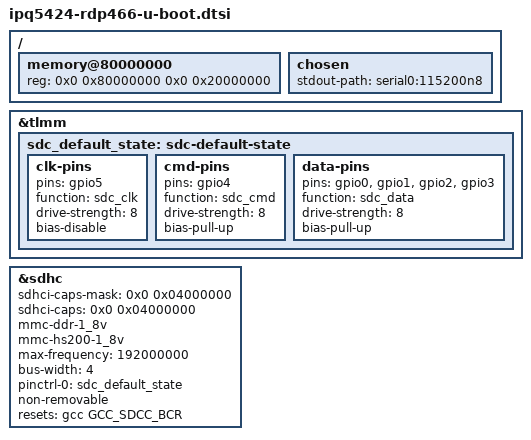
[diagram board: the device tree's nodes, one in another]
// SPDX-License-Identifier: GPL-2.0
/*
 * IPQ5424 RDP466 board device tree source
 *
 * Copyright (c) 2025 The Linux Foundation. All rights reserved.
 */

/ {
	/* Will be removed when SMEM parsing is updated */
	memory@80000000 {
		device_type = "memory";
		reg = <0x0 0x80000000 0x0 0x20000000>;
	};

	chosen {
		stdout-path = "serial0:115200n8";
	};
};

&tlmm {
	/*
	 * v7.1-dts drops this state along with the &sdhc node it served, since
	 * Linux has no user for it. U-Boot still boots from the SD controller,
	 * so carry the pin configuration here.
	 */
	sdc_default_state: sdc-default-state {
		clk-pins {
			pins = "gpio5";
			function = "sdc_clk";
			drive-strength = <8>;
			bias-disable;
		};

		cmd-pins {
			pins = "gpio4";
			function = "sdc_cmd";
			drive-strength = <8>;
			bias-pull-up;
		};

		data-pins {
			pins = "gpio0", "gpio1", "gpio2", "gpio3";
			function = "sdc_data";
			drive-strength = <8>;
			bias-pull-up;
		};
	};
};

	&sdhc {
		sdhci-caps-mask = <0x0 0x04000000>;
		sdhci-caps = <0x0 0x04000000>;	/* SDHCI_CAN_VDD_180 */
		mmc-ddr-1_8v;
		mmc-hs200-1_8v;
		max-frequency = <192000000>;
		bus-width = <4>;
		pinctrl-0 = <&sdc_default_state>;
		pinctrl-names = "default";
		non-removable;

		/*
		 * This reset is needed to clear out the settings done by
		 * previous boot loader. Without this the SDHCI_RESET_ALL
		 * reset done sdhci_init() times out.
		 */
		resets = <&gcc GCC_SDCC_BCR>;

		status = "okay";
	};

